AUTOSAR XML (schema 00050)
package /body_control/lighting/swc
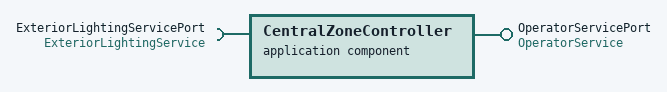
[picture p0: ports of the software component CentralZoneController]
  application sw component type CentralZoneController
    provide port OperatorServicePort: provided-interface=OperatorService
    require port ExteriorLightingServicePort: required-interface=ExteriorLightingService
  application sw component type ExteriorLightingNode
    provide port ExteriorLightingServicePort: provided-interface=ExteriorLightingService
  application sw component type HmiClient
    require port OperatorServicePort: required-interface=OperatorService
  composition sw component type BCL_Composition
    component CentralZoneController: type=CentralZoneController
    component ExteriorLightingNode: type=ExteriorLightingNode
    component HmiClient: type=HmiClient
    connect CentralZoneController.OperatorServicePort -> HmiClient.OperatorServicePort
    connect ExteriorLightingNode.ExteriorLightingServicePort -> CentralZoneController.ExteriorLightingServicePort
